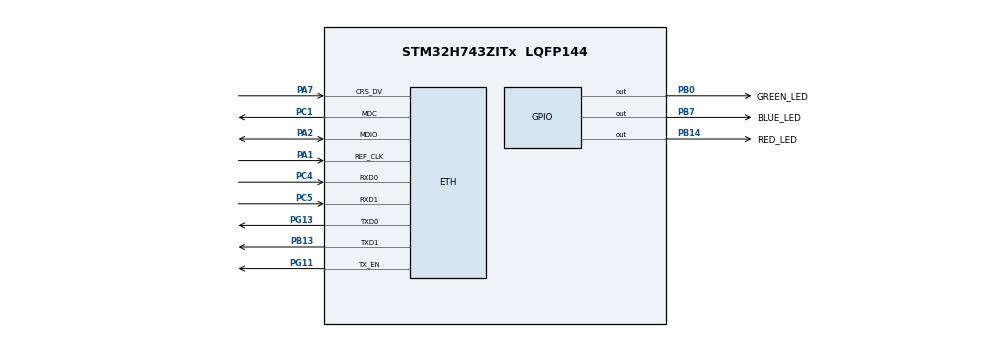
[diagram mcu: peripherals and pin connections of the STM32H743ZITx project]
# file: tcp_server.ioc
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CORTEX_M7.AccessPermission-Cortex_Memory_Protection_Unit_Region0_Settings=MPU_REGION_FULL_ACCESS
CORTEX_M7.AccessPermission-Cortex_Memory_Protection_Unit_Region1_Settings=MPU_REGION_FULL_ACCESS
CORTEX_M7.BaseAddress-Cortex_Memory_Protection_Unit_Region0_Settings=0x30000000
CORTEX_M7.BaseAddress-Cortex_Memory_Protection_Unit_Region1_Settings=0x30004000
CORTEX_M7.CPU_DCache=Enabled
CORTEX_M7.CPU_ICache=Enabled
CORTEX_M7.Enable-Cortex_Memory_Protection_Unit_Region0_Settings=MPU_REGION_ENABLE
CORTEX_M7.Enable-Cortex_Memory_Protection_Unit_Region1_Settings=MPU_REGION_ENABLE
CORTEX_M7.IsBufferable-Cortex_Memory_Protection_Unit_Region0_Settings=MPU_ACCESS_BUFFERABLE
CORTEX_M7.IsShareable-Cortex_Memory_Protection_Unit_Region1_Settings=MPU_ACCESS_SHAREABLE
CORTEX_M7.MPU_Control=MPU_PRIVILEGED_DEFAULT
CORTEX_M7.Size-Cortex_Memory_Protection_Unit_Region0_Settings=MPU_REGION_SIZE_1KB
CORTEX_M7.Size-Cortex_Memory_Protection_Unit_Region1_Settings=MPU_REGION_SIZE_16KB
CORTEX_M7.TypeExtField-Cortex_Memory_Protection_Unit_Region1_Settings=MPU_TEX_LEVEL1
ETH.MediaInterface=HAL_ETH_RMII_MODE
LWIP.BSP.number=1
LWIP.GATEWAY_ADDRESS=010.000.000.001
LWIP.IP_ADDRESS=010.000.000.123
LWIP.LWIP_DHCP=0
LWIP.LWIP_RAM_HEAP_POINTER=0x30004000
LWIP.MEM_SIZE=14*1024
LWIP.NETMASK_ADDRESS=255.255.255.000
LWIP.Version=v2.1.2_Cube
LWIP0.BSP.STBoard=false
LWIP0.BSP.api=BSP_COMPONENT_DRIVER
LWIP0.BSP.component=LAN8742
LWIP0.BSP.instance=LAN8742
LWIP0.BSP.name=Driver_PHY
LWIP0.BSP.semaphore=S_LAN8742
LWIP0.BSP.solution=LAN8742
Mcu.Family=STM32H7
Mcu.Name=STM32H743ZITx
Mcu.Package=LQFP144
NVIC.ETH_IRQn=true\:0\:0\:false\:false\:true\:true\:true\:true
NVIC.PriorityGroup=NVIC_PRIORITYGROUP_4
NVIC.TIM2_IRQn=true\:0\:0\:false\:false\:true\:true\:true\:true
PA1.Mode=RMII
PA1.Signal=ETH_REF_CLK
PA2.Mode=RMII
PA2.Signal=ETH_MDIO
PA7.Mode=RMII
PA7.Signal=ETH_CRS_DV
PB0.GPIO_Label=GREEN_LED
PB0.Signal=GPIO_Output
PB13.Mode=RMII
PB13.Signal=ETH_TXD1
PB14.GPIO_Label=RED_LED
PB14.Signal=GPIO_Output
PB7.GPIO_Label=BLUE_LED
PB7.Signal=GPIO_Output
PC1.Mode=RMII
PC1.Signal=ETH_MDC
PC4.Mode=RMII
PC4.Signal=ETH_RXD0
PC5.Mode=RMII
PC5.Signal=ETH_RXD1
PG11.Mode=RMII
PG11.Signal=ETH_TX_EN
PG13.Mode=RMII
PG13.Signal=ETH_TXD0
PH0-OSC_IN\ (PH0).Mode=HSE-External-Oscillator
PH0-OSC_IN\ (PH0).Signal=RCC_OSC_IN
PH1-OSC_OUT\ (PH1).Mode=HSE-External-Oscillator
PH1-OSC_OUT\ (PH1).Signal=RCC_OSC_OUT
ProjectManager.HeapSize=0x2000
ProjectManager.StackSize=0x4000
ProjectManager.TargetToolchain=STM32CubeIDE
RCC.ADCFreq_Value=50390625
RCC.APB1Freq_Value=120000000
RCC.APB2Freq_Value=120000000
RCC.APB3Freq_Value=120000000
RCC.APB4Freq_Value=120000000
RCC.CortexFreq_Value=480000000
RCC.D1PPRE=RCC_APB3_DIV2
RCC.D2PPRE1=RCC_APB1_DIV2
RCC.D2PPRE2=RCC_APB2_DIV2
RCC.D3PPRE=RCC_APB4_DIV2
RCC.DIVM1=5
RCC.DIVN1=192
RCC.HCLKFreq_Value=240000000
RCC.HPRE=RCC_HCLK_DIV2
RCC.PLLSourceVirtual=RCC_PLLSOURCE_HSE
RCC.SYSCLKFreq_VALUE=480000000
RCC.SYSCLKSource=RCC_SYSCLKSOURCE_PLLCLK
RCC.USBFreq_Value=480000000
TIM2.Period=99999
TIM2.Prescaler=239
VP_LWIP_VS_Enabled.Mode=Enabled
VP_TIM2_VS_ClockSourceINT.Mode=Internal
board=custom

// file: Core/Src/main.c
/* USER CODE BEGIN Header */
/**
  ******************************************************************************
  * @file           : main.c
  * @brief          : Main program body
  ******************************************************************************
  * @attention
  *
  * Copyright (c) 2024 STMicroelectronics.
  * All rights reserved.
  *
  * This software is licensed under terms that can be found in the LICENSE file
  * in the root directory of this software component.
  * If no LICENSE file comes with this software, it is provided AS-IS.
  *
  ******************************************************************************
  */
/* USER CODE END Header */
#include "main.h"
#include "lwip.h"
#include "tim.h"
#include "gpio.h"

/* USER CODE BEGIN Includes */
#include "tcp_server.h"
/* USER CODE END Includes */

void SystemClock_Config(void);
static void MPU_Config(void);

int main(void)
{

  /* MPU Configuration--------------------------------------------------------*/
  MPU_Config();

  /* Enable the CPU Cache */

  /* Enable I-Cache---------------------------------------------------------*/
  SCB_EnableICache();

  /* Enable D-Cache---------------------------------------------------------*/
  SCB_EnableDCache();

  /* MCU Configuration--------------------------------------------------------*/

  /* Reset of all peripherals, Initializes the Flash interface and the Systick. */
  HAL_Init();

  /* Configure the system clock */
  SystemClock_Config();

  /* Initialize all configured peripherals */
  MX_GPIO_Init();
  MX_TIM2_Init();
  MX_LWIP_Init();
  /* USER CODE BEGIN 2 */
  tcp_server_init();
  /* USER CODE END 2 */

  /* Infinite loop */
  while (1)
  {

    /* USER CODE BEGIN 3 */
    MX_LWIP_Process();
  }
  /* USER CODE END 3 */
}

void SystemClock_Config(void)
{
  RCC_OscInitTypeDef RCC_OscInitStruct = {0};
  RCC_ClkInitTypeDef RCC_ClkInitStruct = {0};

  /** Supply configuration update enable
  */
  HAL_PWREx_ConfigSupply(PWR_LDO_SUPPLY);

  /** Configure the main internal regulator output voltage
  */
  __HAL_PWR_VOLTAGESCALING_CONFIG(PWR_REGULATOR_VOLTAGE_SCALE1);

  while(!__HAL_PWR_GET_FLAG(PWR_FLAG_VOSRDY)) {}

  __HAL_RCC_SYSCFG_CLK_ENABLE();
  __HAL_PWR_VOLTAGESCALING_CONFIG(PWR_REGULATOR_VOLTAGE_SCALE0);

  while(!__HAL_PWR_GET_FLAG(PWR_FLAG_VOSRDY)) {}

  /** Initializes the RCC Oscillators according to the specified parameters
  * in the RCC_OscInitTypeDef structure.
  */
  RCC_OscInitStruct.OscillatorType = RCC_OSCILLATORTYPE_HSE;
  RCC_OscInitStruct.HSEState = RCC_HSE_ON;
  RCC_OscInitStruct.PLL.PLLState = RCC_PLL_ON;
  RCC_OscInitStruct.PLL.PLLSource = RCC_PLLSOURCE_HSE;
  RCC_OscInitStruct.PLL.PLLM = 5;
  RCC_OscInitStruct.PLL.PLLN = 192;
  RCC_OscInitStruct.PLL.PLLP = 2;
  RCC_OscInitStruct.PLL.PLLQ = 2;
  RCC_OscInitStruct.PLL.PLLR = 2;
  RCC_OscInitStruct.PLL.PLLRGE = RCC_PLL1VCIRANGE_2;
  RCC_OscInitStruct.PLL.PLLVCOSEL = RCC_PLL1VCOWIDE;
  RCC_OscInitStruct.PLL.PLLFRACN = 0;
  if (HAL_RCC_OscConfig(&RCC_OscInitStruct) != HAL_OK)
  {
    Error_Handler();
  }

  /** Initializes the CPU, AHB and APB buses clocks
  */
  RCC_ClkInitStruct.ClockType = RCC_CLOCKTYPE_HCLK|RCC_CLOCKTYPE_SYSCLK
                              |RCC_CLOCKTYPE_PCLK1|RCC_CLOCKTYPE_PCLK2
                              |RCC_CLOCKTYPE_D3PCLK1|RCC_CLOCKTYPE_D1PCLK1;
  RCC_ClkInitStruct.SYSCLKSource = RCC_SYSCLKSOURCE_PLLCLK;
  RCC_ClkInitStruct.SYSCLKDivider = RCC_SYSCLK_DIV1;
  RCC_ClkInitStruct.AHBCLKDivider = RCC_HCLK_DIV2;
  RCC_ClkInitStruct.APB3CLKDivider = RCC_APB3_DIV2;
  RCC_ClkInitStruct.APB1CLKDivider = RCC_APB1_DIV2;
  RCC_ClkInitStruct.APB2CLKDivider = RCC_APB2_DIV2;
  RCC_ClkInitStruct.APB4CLKDivider = RCC_APB4_DIV2;

  if (HAL_RCC_ClockConfig(&RCC_ClkInitStruct, FLASH_LATENCY_4) != HAL_OK)
  {
    Error_Handler();
  }
}

 /* MPU Configuration */

void MPU_Config(void)
{
  MPU_Region_InitTypeDef MPU_InitStruct = {0};

  /* Disables the MPU */
  HAL_MPU_Disable();

  /** Initializes and configures the Region and the memory to be protected
  */
  MPU_InitStruct.Enable = MPU_REGION_ENABLE;
  MPU_InitStruct.Number = MPU_REGION_NUMBER0;
  MPU_InitStruct.BaseAddress = 0x30000000;
  MPU_InitStruct.Size = MPU_REGION_SIZE_1KB;
  MPU_InitStruct.SubRegionDisable = 0x0;
  MPU_InitStruct.TypeExtField = MPU_TEX_LEVEL0;
  MPU_InitStruct.AccessPermission = MPU_REGION_FULL_ACCESS;
  MPU_InitStruct.DisableExec = MPU_INSTRUCTION_ACCESS_ENABLE;
  MPU_InitStruct.IsShareable = MPU_ACCESS_NOT_SHAREABLE;
  MPU_InitStruct.IsCacheable = MPU_ACCESS_NOT_CACHEABLE;
  MPU_InitStruct.IsBufferable = MPU_ACCESS_BUFFERABLE;

  HAL_MPU_ConfigRegion(&MPU_InitStruct);

  /** Initializes and configures the Region and the memory to be protected
  */
  MPU_InitStruct.Number = MPU_REGION_NUMBER1;
  MPU_InitStruct.BaseAddress = 0x30004000;
  MPU_InitStruct.Size = MPU_REGION_SIZE_16KB;
  MPU_InitStruct.TypeExtField = MPU_TEX_LEVEL1;
  MPU_InitStruct.IsShareable = MPU_ACCESS_SHAREABLE;
  MPU_InitStruct.IsBufferable = MPU_ACCESS_NOT_BUFFERABLE;

  HAL_MPU_ConfigRegion(&MPU_InitStruct);
  /* Enables the MPU */
  HAL_MPU_Enable(MPU_PRIVILEGED_DEFAULT);

}

void Error_Handler(void)
{
  __disable_irq();
  while (1)
  {
  }
}
